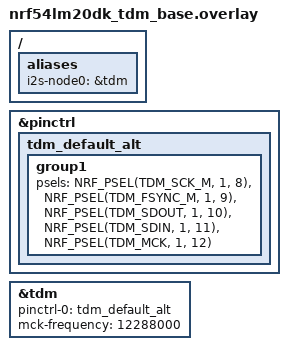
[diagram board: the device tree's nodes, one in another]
/*
 * Copyright (c) 2026 Nordic Semiconductor ASA
 *
 * SPDX-License-Identifier: Apache-2.0
 */

/* Base overlay for exercising the TDM clock-state cases on nRF54LM20. It is selected explicitly
 * (never as a board-named overlay) and layered with one nrf54lm20dk_tdm_*.overlay that adds the
 * clock state(s). nRF54LM20 has no I2S; TDM is its audio peripheral and implements the I2S API,
 * so it is used as i2s-node0.
 */
/ {
	aliases {
		i2s-node0 = &tdm;
	};
};

&pinctrl {
	tdm_default_alt: tdm_default_alt {
		group1 {
			psels = <NRF_PSEL(TDM_SCK_M, 1, 8)>,
				<NRF_PSEL(TDM_FSYNC_M, 1, 9)>,
				<NRF_PSEL(TDM_SDOUT, 1, 10)>,
				<NRF_PSEL(TDM_SDIN, 1, 11)>,
				<NRF_PSEL(TDM_MCK, 1, 12)>;
		};
	};
};

&tdm {
	status = "okay";
	pinctrl-0 = <&tdm_default_alt>;
	pinctrl-names = "default";
	mck-frequency = <12288000>;
};
